# ATtiny1624 device description
Architecture: AVR8X; Family: tinyAVR 2
Registers are 8-bit, read-write, reset 0x0 unless marked. A register's access mark holds for its fields unless they carry their own. Offsets are from the block's base; [hi:lo] are bit positions; {n}, {i} and the like mark numbered series.

## ADC — Analog to Digital Converter
Instances: ADC0 0x0600
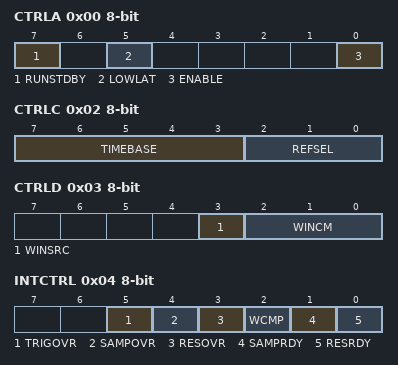
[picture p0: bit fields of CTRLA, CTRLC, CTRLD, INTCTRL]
0x00 CTRLA — Control A
  [7] RUNSTDBY — Run standby mode
  [5] LOWLAT — ADC Low latency mode
  [0] ENABLE — ADC Enable
0x01 CTRLB — Control B
  [3:0] PRESC — Prescaler Value
    0=DIV2 (System clock divided by 2); 1=DIV4 (System clock divided by 4); 2=DIV6 (System clock divided by 6); 3=DIV8 (System clock divided by 8); 4=DIV10 (System clock divided by 10); 5=DIV12 (System clock divided by 12); 6=DIV14 (System clock divided by 14); 7=DIV16 (System clock divided by 16); 8=DIV20 (System clock divided by 20); 9=DIV24 (System clock divided by 24); 10=DIV28 (System clock divided by 28); 11=DIV32 (System clock divided by 32); 12=DIV40 (System clock divided by 40); 13=DIV48 (System clock divided by 48); 14=DIV56 (System clock divided by 56); 15=DIV64 (System clock divided by 64)
0x02 CTRLC — Control C
  [7:3] TIMEBASE — Reference Selection
  [2:0] REFSEL — Reference select
    0=VDD; 2=VREFA (External Reference); 4=1024MV (Internal 1.024V Reference); 5=2048MV (Internal 2.048V Reference); 6=2500MV (Internal 2.5V Reference); 7=4096MV (Internal 4.096V Reference)
0x03 CTRLD — Control D
  [3] WINSRC — Window Mode Source
    0=RESULT; 1=SAMPLE
  [2:0] WINCM — Window Comparator Mode
    0=NONE (No Window Comparison); 1=BELOW (Below Window); 2=ABOVE (Above Window); 3=INSIDE (Inside Window); 4=OUTSIDE (Outside Window)
0x04 INTCTRL — Interrupt Control
  [5] TRIGOVR — Trigger Overrun Interrupt Enable
  [4] SAMPOVR — Sample Overwritten Interrupt Enable
  [3] RESOVR — Result Overwritten Interrupt Enable
  [2] WCMP — Window Comparator Interrupt Enable
  [1] SAMPRDY — Sample Ready Interrupt Enable
  [0] RESRDY — Result Ready Interrupt Enable
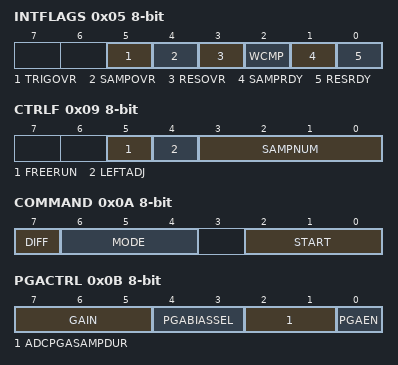
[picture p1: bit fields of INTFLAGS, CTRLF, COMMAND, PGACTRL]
0x05 INTFLAGS — Interrupt Flags
  [5] TRIGOVR — Trigger Overrun Interrupt Flag
  [4] SAMPOVR — Sample Overwritten Interrupt Flag
  [3] RESOVR — Result Overwritten Interrupt Flag
  [2] WCMP — Window Comparator Interrupt Flag
  [1] SAMPRDY — Sample Ready Interrupt Flag
  [0] RESRDY — Result Ready Interrupt Flag
0x06 STATUS ro
  [0] ADCBUSY
0x07 DBGCTRL — Debug Control
  [0] DBGRUN — Debug run
0x08 CTRLE — Control E
  [7:0] SAMPDUR — Sampling time
0x09 CTRLF — Control F
  [5] FREERUN — Free running mode
  [4] LEFTADJ — Left adjust
  [3:0] SAMPNUM — Sample numbers
    0=NONE (No accumulation); 1=ACC2 (2 samples accumulation); 2=ACC4 (4 samples accumulation); 3=ACC8 (8 samples accumulation); 4=ACC16 (16 samples accumulation); 5=ACC32 (32 samples accumulation); 6=ACC64 (64 samples accumulation); 7=ACC128 (128 samples accumulation); 8=ACC256 (256 samples accumulation); 9=ACC512 (512 samples accumulation); 10=ACC1024 (1024 samples accumulation)
0x0A COMMAND
  [7] DIFF — Differential mode
  [6:4] MODE
    0=SINGLE_8BIT (Single Conversion 8-bit); 1=SINGLE_12BIT (Single Conversion 12-bit); 2=SERIES (Series Accumulation); 3=SERIES_SCALING (Series Accumulation with Scaling); 4=BURST (Burst Accumulation); 5=BURST_SCALING (Burst Accumulation with Scaling)
  [2:0] START — Start command
    0=STOP (Stop an ongoing conversion); 1=IMMEDIATE (Start immediately); 2=MUXPOS_WRITE (Start on MUXPOS write); 3=MUXNEG_WRITE (Start on MUXNEG write); 4=EVENT_TRIGGER (Start on event)
0x0B PGACTRL — PGA Control
  [7:5] GAIN
    0=1X Gain; 1=2X (2X Gain); 2=4X (4X Gain); 3=8X (8X Gain); 4=16X (16X Gain)
  [4:3] PGABIASSEL — PGA BIAS Select
    0=1x BIAS current; 1=3_4X (3/4x BIAS current); 2=1_2X (1/2x BIAS current); 3=1_4X (1/4x BIAS current)
  [2:1] ADCPGASAMPDUR — ADC PGA Sample Duration
    0=6CLK (6 ADC cycles); 1=15CLK (15 ADC cycles); 2=20CLK (20 ADC cycles); 3=32CLK (32 ADC cycles)
  [0] PGAEN — PGA Enable
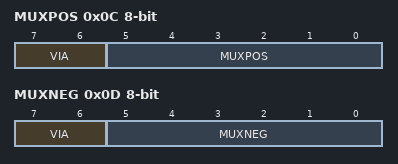
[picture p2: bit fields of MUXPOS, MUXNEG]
0x0C MUXPOS — Positive mux input
  [7:6] VIA
    0=ADC (Via ADC); 1=PGA (Via PGA)
  [5:0] MUXPOS — Analog Channel Selection Bits
    {v}=AIN{v} (ADC input pin {v}) (v=1..7); 10=AIN10 (ADC input pin 10); 11=AIN11 (ADC input pin 11); 48=GND (Ground); 49=VDDDIV10 (VDD/10); 50=TEMPSENSE (Temperature sensor); 51=DACREF0 (DACREF from AC0)
0x0D MUXNEG — Negative mux input
  [7:6] VIA
    0=ADC (Via ADC); 1=PGA (Via PGA)
  [5:0] MUXNEG — Analog Channel Selection Bits
    {v}=AIN{v} (ADC input pin {v}) (v=1..7); 48=GND (Ground); 49=VDDDIV10 (VDD/10); 51=DACREF0 (DACREF from AC0)
0x10 RESULT 32-bit ro reset not defined
0x14 SAMPLE 16-bit ro reset not defined
0x18 TEMP0 — Temporary Data 0
  [7:0] TEMP — Temporary
0x19 TEMP1 — Temporary Data 1
  [7:0] TEMP — Temporary
0x1A TEMP2 reset not defined — Temporary Data 2
  [7:0] TEMP — Temporary
0x1C WINLT 16-bit reset not defined — Window Low Threshold
0x1E WINHT 16-bit reset not defined — Window High Threshold
